# rCSL_tmr_001 register map
Vendor: Texas Instruments
Peripheral module from a debugger description file (folder c674x).
Registers are 32-bit, read-write, reset 0x0 unless marked. A register's access mark holds for its fields unless they carry their own. Offsets are as the file gives them; lines under a group give offsets from that group; [hi:lo] are bit positions; {n}, {i} and the like mark numbered series; 'fields as' and 'values as' point back to an identical list; <NAME> marks a mode.

## TMR
0x00 REV access not given reset 0x44720211 — Peripheral ID Register
  [31:0] REGVAL
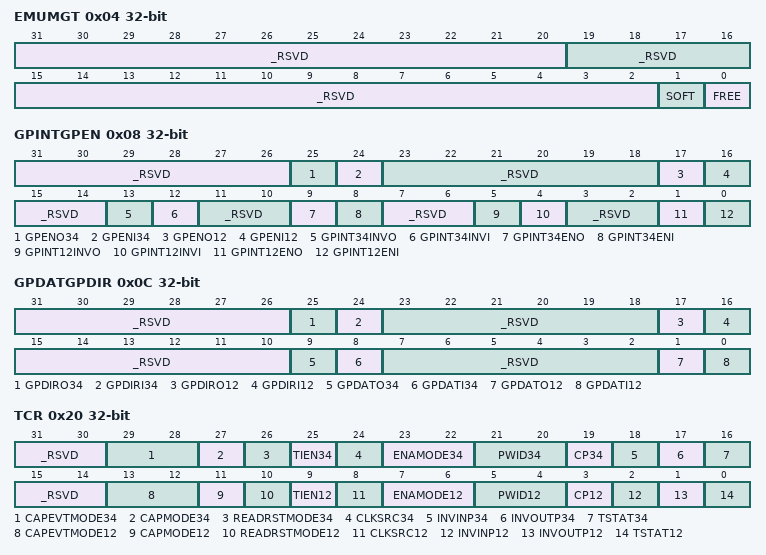
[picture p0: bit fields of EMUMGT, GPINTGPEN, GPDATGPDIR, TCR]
0x04 EMUMGT access not given — Emulation Management/Clock Speed Registers
  [31:20] _RSVD — (access N)
  [19:16] _RSVD — Divided CPU and VBUS Clock Speed Ratios (access N)
  [15:2] _RSVD — (access N)
  [1] SOFT rw — Determines emulation mode of timer.
    0=IMMEDIATE; 1=INCREMENT
  [0] FREE rw — Determines emulation mode of timer.
    0=SOFT; 1=FREE
0x08 GPINTGPEN access not given — GPIO IO Interrupt Control and Enable Registers
  [31:26] _RSVD — (access N)
  [25] GPENO34 rw — Enable TOUTP34 in GPIO mode
    0=TIMER; 1=GPIO
  [24] GPENI34 rw — Enable TINP34 in GPIO mode
    0=TIMER; 1=GPIO
  [23:18] _RSVD — (access N)
  [17] GPENO12 rw — Enable TOUTP12 in GPIO mode
    0=TIMER (TOUTP12 functions as timer output); 1=GPIO (TOUTP12 is enabled as GPIO)
  [16] GPENI12 rw — Enable TINP12 in GPIO mode
    0=TIMER (TINP12 functions as timer input); 1=GPIO (TINP12 is enabled as GPIO)
  [15:14] _RSVD — (access N)
  [13] GPINT34INVO rw — Invert bit for TOUTP34 when GPINT34_ENO = 1
    0=DISABLE; 1=ENABLE
  [12] GPINT34INVI rw — Invert bit for TINP34 when GPINT34_ENI = 1
    0=DISABLE; 1=ENABLE
  [11:10] _RSVD — (access N)
  [9] GPINT34ENO rw — Enable TOUTP34 to source int or evt in GPIO mode
    0=DISABLE; 1=ENABLE
  [8] GPINT34ENI rw — Enable TINP34 to source int or evt in GPIO mode
    0=DISABLE; 1=ENABLE
  [7:6] _RSVD — (access N)
  [5] GPINT12INVO rw — Invert bit for TOUTP12 when GPINT12_ENO = 1
    0=DISABLE (Timer output interrupt or event is not inverted); 1=ENABLE (Timer output interrupt or event is inverted)
  [4] GPINT12INVI rw — Invert bit for TINP12 when GPINT12_ENI = 1
    0=DISABLE (Timer input interrupt or event is not inverted); 1=ENABLE (Timer input interrupt or event is inverted)
  [3:2] _RSVD — (access N)
  [1] GPINT12ENO rw — Enable TOUTP12 to source int or evt in GPIO mode
    0=DISABLE (Interrupt or event sourced normally by timer); 1=ENABLE (Timer input sources interrupt or event)
  [0] GPINT12ENI rw — Enable TINP12 to source int or evt in GPIO mode
    values as GPINT12ENO
0x0C GPDATGPDIR access not given — General Purpose IO Data and Direction registers
  [31:26] _RSVD — (access N)
  [25] GPDIRO34 rw — Controls direction of TOUTP34 in GPIO mode
    0=INPUT; 1=OUTPUT
  [24] GPDIRI34 rw — Controls direction of TINP34 in GPIO mode
    0=INPUT; 1=OUTPUT
  [23:18] _RSVD — (access N)
  [17] GPDIRO12 rw — Controls direction of TOUTP12 in GPIO mode
    0=INPUT (GPIO Input); 1=OUTPUT (GPIO Output)
  [16] GPDIRI12 rw — Controls direction of TINP12 in GPIO mode
    0=INPUT (GPIO Input); 1=OUTPUT (GPIO Output)
  [15:10] _RSVD — (access N)
  [9] GPDATO34 rw — Value present on TOUTP34 when GPIO_DIRO34 = 0; or value to output on TOUTP34 when GPIO_DIRO34 = 1
    0=CLR; 1=SET
  [8] GPDATI34 rw — Value present on TINP34 when GPIO_DIRI34 = 0; or value to output on TINP34 when GPIO_DIRI34 = 1
    0=CLR; 1=SET
  [7:2] _RSVD — (access N)
  [1] GPDATO12 rw — Value present on TOUTP12 when GPIO_DIRO12 = 0; or value to output on TOUTP12 when GPIO_DIRO12 = 1
    0=CLR; 1=SET
  [0] GPDATI12 rw — Value present on TINP12 when GPIO_DIRI12 = 0; or value to output on TINP12 when GPIO_DIRI12 = 1
    0=CLR; 1=SET
0x10 TIM12 — Timer Counter Register 12
0x14 TIM34 — Timer Counter Register 34
0x18 PRD12 — Timer Period Register 12
0x1C PRD34 — Timer Period Register 34
0x20 TCR access not given — Timer Control Register
  [31:30] _RSVD — (access N)
  [29:28] CAPEVTMODE34 rw — Determines event generation from TINP34 when CAPMODE34 = 1; INVINP does not effect edge detection.
    0=RISE; 1=FALL; 2=BOTH
  [27] CAPMODE34 rw — Determines whether the timer is to be run in capture mode or not
    0=DISABLE; 1=ENABLE
  [26] READRSTMODE34 rw — Determines the effect of a timer counter read on TIMx
    0=CONTINUE (No effect of timer counter read); 1=RESET (Timer counter is reset; If ENAMODE=11, value of PERIOD is restored from RELOAD and timer continues counting)
  [25] TIEN34 rw — Determines if clock is gated by timer input when CLKSRC=0
    0=NOTGATED; 1=GATED
  [24] CLKSRC34 rw — Determines the selected clock source for timer
    0=INTERNAL; 1=TIMER
  [23:22] ENAMODE34 rw — Determines enabling modes of the timer
    0=DISABLE (Timer disabled and maintains current value); 1=EN_ONCE (Timer enabled one time; stops upon reaching PRD); 2=EN_CONT (Timer enabled continuously; TIMx increments until counter matches PRD, resets to 0 on next cycle.); 3=EN_CONTRELOAD (Timer enabled continuously; TIMx increments until counter matches PRD, resets to 0, updates PRD with Reload registers and continues.)
  [21:20] PWID34 rw — Pulse width when CP=0
    0=ONE_CLK; 1=TWO_CLK; 2=THREE_CLK; 3=FOUR_CLK
  [19] CP34 rw — Clock pulse mode for timer output
    0=PULSE; 1=CLOCK
  [18] INVINP34 rw — Timer input inverter control when CLKSRC=1
    0=NON_INVERTED; 1=INVERTED
  [17] INVOUTP34 rw — Timer output inverter control
    0=NON_INVERTED; 1=INVERTED
  [16] TSTAT34 ro — Timer status; Value of timer output; Inverted by INVOUTP
    0=LOW; 1=HIGH
  [15:14] _RSVD — (access N)
  [13:12] CAPEVTMODE12 rw — Determines event generation from TINP12 when CAPMODE12 = 1; INVINP does not effect edge detection.
    0=RISE (Event on rising edge); 1=FALL (Event on falling edge); 2=BOTH (Event on both edges)
  [11] CAPMODE12 rw — Determines whether the timer is to be run in capture mode or not
    0=DISABLE (Timer not in capture mode); 1=ENABLE (Timer in caputre mode when CLKSRC=0, TIEN=0, ENAMODE=1x)
  [10] READRSTMODE12 rw — Determines the effect of a timer counter read on TIMx
    values as READRSTMODE34
  [9] TIEN12 rw — Determines if clock is gated by timer input when CLKSRC=0
    0=NOTGATED (Timer clock not gated by timer input); 1=GATED (Timer clock gated by timer input)
  [8] CLKSRC12 rw — Determines the selected clock source for timer
    0=INTERNAL (VBUS Clock); 1=TIMER (Timer Input pin)
  [7:6] ENAMODE12 rw — Determines enabling modes of the timer
    values as ENAMODE34
  [5:4] PWID12 rw — Pulse width when CP=0
    0=ONE_CLK (TSTATx goes inactive one timer clock cycle after TIMx reaches period); 1=TWO_CLK (TSTATx goes inactive two timer clock cycles after TIMx reaches period); 2=THREE_CLK (TSTATx goes inactive three timer clock cycles after TIMx reaches period); 3=FOUR_CLK (TSTATx goes inactive four timer clock cycles after TIMx reaches period)
  [3] CP12 rw — Clock pulse mode for timer output
    0=PULSE (Pulse Mode; TSTATx is active one timer clock after TIMx reaches PRD. PWID determines when it goes inactive.); 1=CLOCK (Clock Mode; TIN/TOUT is 50% duty cycle & toggles when timer reaches zero.)
  [2] INVINP12 rw — Timer input inverter control when CLKSRC=1
    0=NON_INVERTED (Uninverted input drives timer); 1=INVERTED (Inverted input drives timer)
  [1] INVOUTP12 rw — Timer output inverter control
    0=NON_INVERTED (Uninverted timer output); 1=INVERTED (Inverted timer output)
  [0] TSTAT12 ro — Timer status; Value of timer output; Inverted by INVOUTP
    0=LOW; 1=HIGH
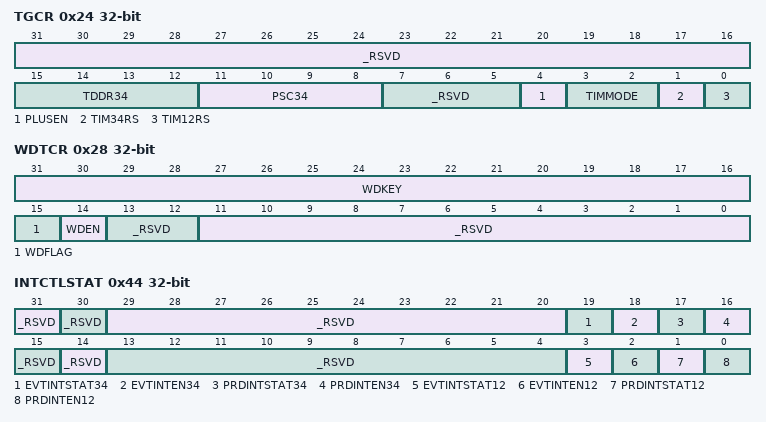
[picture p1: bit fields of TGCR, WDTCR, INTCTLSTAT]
0x24 TGCR access not given — Timer Global Control Register
  [31:16] _RSVD — (access N)
  [15:12] TDDR34 rw — Linear divide-down ratio for TIM34
  [11:8] PSC34 rw — Pre-scalar counter for TIM34
  [7:5] _RSVD — (access N)
  [4] PLUSEN rw — Enables Plus features
    0=DISABLE (Backward compatible with Timer64); 1=ENABLE (New Timer64p features used)
  [3:2] TIMMODE rw — Determines timer modes
    0=64BIT_GPT; 1=32BIT_UNCHAIN; 2=64BIT_WDT; 3=32_CHAIN
  [1] TIM34RS rw — TIM34 reset
    0=RESET; 1=NO_RESET
  [0] TIM12RS rw — TIM12 reset
    0=RESET; 1=NO_RESET
0x28 WDTCR access not given — Watchdog Timer Control Register
  [31:16] WDKEY rw — Watchdog reset key: 0xA5C6 -> 0xDA7E
  [15] WDFLAG rw — Watchdog flag bit
    0=NO_TIMEOUT; 1=TIMEOUT
  [14] WDEN rw — Watchdog enable bit
    0=DISABLE; 1=ENABLE
  [13:12] _RSVD — Watchdog idle key: 0b01 -> 0b10 (access N)
    1=CMD1; 2=CMD2
  [11:0] _RSVD — (access N)
0x34 REL12 — Timer Reload Register 12
0x38 REL34 — Timer Reload Register 34
0x3C CAP12 — Timer capture (shadow) register 12
0x40 CAP34 — Timer capture (shadow) register 34
0x44 INTCTLSTAT access not given — Timer interrupt control and status register
  [31] _RSVD — Used for test purposes to pulse the interrupt regardless of interrupt settings (access N)
  [30] _RSVD — Used to pulse the interrupt only if it is enabled (access N)
  [29:20] _RSVD — (access N)
  [19] EVTINTSTAT34 rw — Interrupt status for external event causing a timeout when CAPMODE=1 & BW_COMPATIBLE=1
    0=NOPEND; 1=PEND
  [18] EVTINTEN34 rw — Enables interrupt generation for when an external event causes a timeout & CAPMODE=1 & BW_COMPATIBLE=1
    0=DISABLE; 1=ENABLE
  [17] PRDINTSTAT34 rw — Interrupt status for TIM vs PRD
    0=NOPEND; 1=PEND
  [16] PRDINTEN34 rw — Enables interrupt generation for TIM vs PRD when BW_COMPATIBLE=1
    0=DISABLE; 1=ENABLE
  [15] _RSVD — Used for test purposes to pulse the interrupt regardless of interrupt settings (access N)
  [14] _RSVD — Used to pulse the interrupt only if it is enabled (access N)
  [13:4] _RSVD — (access N)
  [3] EVTINTSTAT12 rw — Interrupt status for external event causing a timeout when CAPMODE=1 & BW_COMPATIBLE=1
    0=NOPEND; 1=PEND
  [2] EVTINTEN12 rw — Enables interrupt generation for when an external event causes a timeout & CAPMODE=1 & BW_COMPATIBLE=1
    0=DISABLE; 1=ENABLE
  [1] PRDINTSTAT12 rw — Interrupt status for TIM vs PRD
    0=NOPEND; 1=PEND
  [0] PRDINTEN12 rw — Enables interrupt generation for TIM vs PRD when BW_COMPATIBLE=1
    0=DISABLE; 1=ENABLE
{0x60+4i} CMP{i} reset 0xFFFFFFFF (i=0..7) — Timer 12 Compare Register {i}
